# AVR16LA32 device description
Architecture: AVR8X; Family: AVR
Registers are 8-bit, read-write, reset 0x0 unless marked. A register's access mark holds for its fields unless they carry their own. Offsets are from the block's base; [hi:lo] are bit positions; {n}, {i} and the like mark numbered series; 'fields as' and 'values as' point back to an identical list.

## GPR — General Purpose Registers
Instances: GPR 0x001C
{0x0+i} GPR{i} reset not defined (i=0..3) — General Purpose Register {i}

## LOCK — Lockbits
Instances: LOCK 0x1040
0x00 KEY 32-bit reset 0x5CC5C55C — Lock Key Bits
  [31:0] KEY — Lock Key
    0x5CC5C55C=NOLOCK (No locks); 0xA33A3AA3=RWLOCK (Read and write lock)

## NVMCTRL — Non-volatile Memory Controller
Instances: NVMCTRL 0x1000
0x00 CTRLA — Control A
  [6:0] CMD — Command
    0=NOCMD (No Command); 1=NOOP (No Operation); 4=FLPW (Flash Page Write); 5=FLPERW (Flash Page Erase and Write); 8=FLPER (Flash Page Erase); 9=FLMPER2 (Flash 2-page erase enable); 10=FLMPER4 (Flash 4-page erase enable); 11=FLMPER8 (Flash 8-page erase enable); 12=FLMPER16 (Flash 16-page erase enable); 13=FLMPER32 (Flash 32-page erase enable); 15=FLPBCLR (Flash Page Buffer Clear); 20=EEPW (EEPROM Page Write); 21=EEPERW (EEPROM Page Erase and Write); 23=EEPER (EEPROM Page Erase); 31=EEPBCLR (EEPROM Page Buffer Clear); 32=CHER (Chip Erase Command (UPDI only)); 48=EECHER (EEPROM Erase Command (UPDI only))
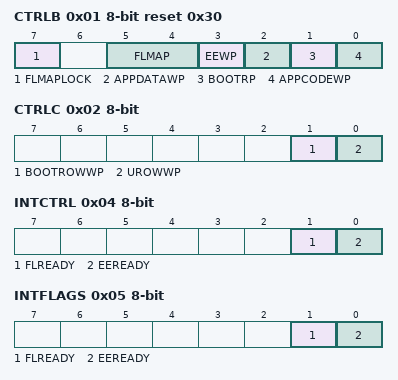
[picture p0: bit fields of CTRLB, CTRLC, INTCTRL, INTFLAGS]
0x01 CTRLB reset 0x30 — Control B
  [7] FLMAPLOCK — Flash Mapping Lock
  [5:4] FLMAP — Flash Mapping in Data space
    0=SECTION0 (Flash section 0, 0 - 32KB); 1=SECTION1 (Flash section 1, 32 - 64KB); 2=SECTION2 (Flash section 2, 64 - 96KB); 3=SECTION3 (Flash section 3, 96 - 128KB)
  [3] EEWP — EEPROM Write Protect
  [2] APPDATAWP — Application Data Write Protect
  [1] BOOTRP — Boot Read Protect
  [0] APPCODEWP — Application Code Write Protect
0x02 CTRLC — Control C
  [1] BOOTROWWP — Boot Row Write Protect
  [0] UROWWP — User Row Write Protect
0x04 INTCTRL — Interrupt Control
  [1] FLREADY — Flash Ready
  [0] EEREADY — EEPROM Ready
0x05 INTFLAGS — Interrupt Flags
  [1] FLREADY — Flash Ready
  [0] EEREADY — EEPROM Ready
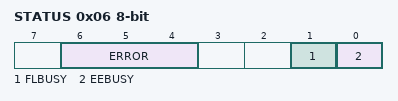
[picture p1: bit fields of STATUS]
0x06 STATUS
  [6:4] ERROR — Write error
    0=NOERROR; 2=WRITEPROTECT (Attempt to program write protected area); 3=CMDCOLLISION (Selecting new write command while write command already seleted); 4=WRONGSECTION (Address cannot be written with selected command)
  [1] FLBUSY ro — Flash busy
  [0] EEBUSY ro — EEPROM busy
0x08 DATA 16-bit
0x0C ADDR 32-bit — Address
  [23:0] ADDR

## PORT — I/O Ports
Instances: PORTA 0x0400, PORTC 0x0440, PORTD 0x0460, PORTF 0x04A0
0x00 DIR — Data Direction
0x01 DIRSET — Data Direction Set
0x02 DIRCLR — Data Direction Clear
0x03 DIRTGL — Data Direction Toggle
0x04 OUT — Output Value
0x05 OUTSET — Output Value Set
0x06 OUTCLR — Output Value Clear
0x07 OUTTGL — Output Value Toggle
0x08 IN — Input Value
0x09 INTFLAGS — Interrupt Flags
  [7:0] INT — Pin Interrupt Flag
0x0A PORTCTRL — Port Control
  [0] SRL — Slew Rate Limit Enable
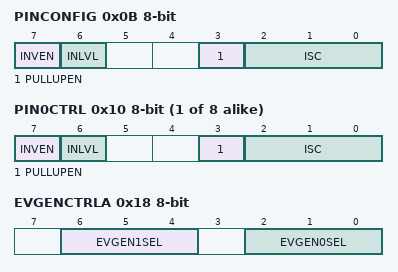
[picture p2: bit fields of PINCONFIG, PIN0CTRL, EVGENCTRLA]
0x0B PINCONFIG — Pin Control Config
  [7] INVEN — Inverted I/O Enable
  [6] INLVL — Input Level Select
    0=ST (Schmitt-Trigger input level); 1=TTL (TTL Input level)
  [3] PULLUPEN — Pullup enable
  [2:0] ISC — Input/Sense Configuration
    0=INTDISABLE (Interrupt disabled but input buffer enabled); 1=BOTHEDGES (Sense Both Edges); 2=RISING (Sense Rising Edge); 3=FALLING (Sense Falling Edge); 4=INPUT_DISABLE (Digital Input Buffer disabled); 5=LEVEL (Sense low Level)
0x0C PINCTRLUPD — Pin Control Update
0x0D PINCTRLSET — Pin Control Set
0x0E PINCTRLCLR — Pin Control Clear
{0x10+i} PIN{i}CTRL (i=0..7) — Pin {i} Control
  fields as PINCONFIG
0x18 EVGENCTRLA — Event Generation Control A
  [6:4] EVGEN1SEL — Event Generator 1 Select
    {v}=PIN{v} (Pin {v} used as event generator) (v=0..7)
  [2:0] EVGEN0SEL — Event Generator 0 Select
    {v}=PIN{v} (Pin {v} used as event generator) (v=0..7)

## PORTMUX — Port Multiplexer
Instances: PORTMUX 0x05E0
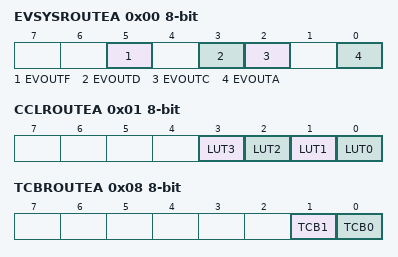
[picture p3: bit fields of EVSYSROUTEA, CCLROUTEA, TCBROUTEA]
0x00 EVSYSROUTEA
  [5] EVOUTF — Event Output F
    0=DEFAULT (EVOUTF: PF2); 1=ALT1 (EVOUTF: PF7)
  [3] EVOUTD — Event Output D
    0=DEFAULT (EVOUTD: PD2); 1=ALT1 (EVOUTD: PD7)
  [2] EVOUTC — Event Output C
    0=DEFAULT (EVOUTC: PC2)
  [0] EVOUTA — Event Output A
    0=DEFAULT (EVOUTA: PA2); 1=ALT1 (EVOUTA: PA7)
0x01 CCLROUTEA
  [3] LUT3 — CCL Look-Up Table 3 Signals
    0=DEFAULT (INn: PF0, PF1, PF2. OUT: PF3.)
  [2] LUT2 — CCL Look-Up Table 2 Signals
    0=DEFAULT (INn: PD0, PD1, PD2. OUT: PD3.); 1=ALT1 (INn: PD0, PD1, PD2. OUT: PD6.)
  [1] LUT1 — CCL Look-Up Table 1 Signals
    0=DEFAULT (INn: PC0, PC1, PC2. OUT: PC3.)
  [0] LUT0 — CCL Look-Up Table 0 Signals
    0=DEFAULT (INn: PA0, PA1, PA2. OUT: PA3.); 1=ALT1 (INn: PA0, PA1, PA2. OUT: PA6.)
0x02 USARTROUTEA
  [2:0] USART0 — USART0 Routing
    0=DEFAULT (TxD: PA0, RxD: PA1, AUX0: PA2, AUX1: PA3); 1=ALT1 (TxD: PA4, RxD: PA5, AUX0: PA6, AUX1: PA7); 2=ALT2 (TxD: PA2, RxD: PA3, AUX0: -, AUX1: -); 3=ALT3 (TxD: PD4, RxD: PD5, AUX0: PD6, AUX1: PD7); 4=ALT4 (TxD: PC1, RxD: PC2, AUX0: PC3, AUX1: -); 6=ALT6 (TxD: PF7, RxD: PF6, AUX0: -, AUX1: -); 7=NONE (Not connected to any pins)
0x05 SPIROUTEA
  [2:0] SPI0 — SPI0 Signals
    0=DEFAULT (MOSI: PA4, MISO: PA5, SCK: PA6, SS: PA7); 3=ALT3 (MOSI: PA0, MISO: PA1, SCK: PC0, SS: PC1); 4=ALT4 (MOSI: PD4, MISO: PD5, SCK: PD6, SS: PD7); 5=ALT5 (MOSI: PC0, MISO: PC1, SCK: PC2, SS: PC3); 6=ALT6 (MOSI: PC1, MISO: PC2, SCK: PC3, SS: PF7); 7=NONE (Not connected to any pins, SS set to 1)
0x06 TWIROUTEA
  [1:0] TWI0 — TWI0 Signals
    0=DEFAULT (SDA: PA2, SCL: PA3. Dual mode: SDA: PC2, SCL: PC3.); 1=ALT1 (SDA: PA2, SCL: PA3. Dual mode: SDA: -, SCL: -.); 2=ALT2 (SDA: PC2, SCL: PC3. Dual mode: SDA: -, SCL: -.); 3=ALT3 (SDA: PA0, SCL: PA1. Dual mode: SDA: PC2, SCL: PC3.)
0x07 TCEROUTEA
  [2:0] TCE0 — TCE0 Signals
    0=PORTA (WOn: PA0, PA1, PA2); 2=PORTC (WOn: PC0, PC1, PC2); 3=PORTD (WOn: PD0, PD1, PD2); 5=PORTF (WOn: PF0, PF1, PF2)
0x08 TCBROUTEA
  [1] TCB1 — TCB1 Output
    0=DEFAULT (WO: PA3); 1=ALT1 (WO: PF5)
  [0] TCB0 — TCB0 Output
    0=DEFAULT (WO: PA2); 1=ALT1 (WO: PF4)
0x0A ACROUTEA
  [0] AC0 — Analog Comparator 0 Output
    0=DEFAULT (OUT: PA7)
